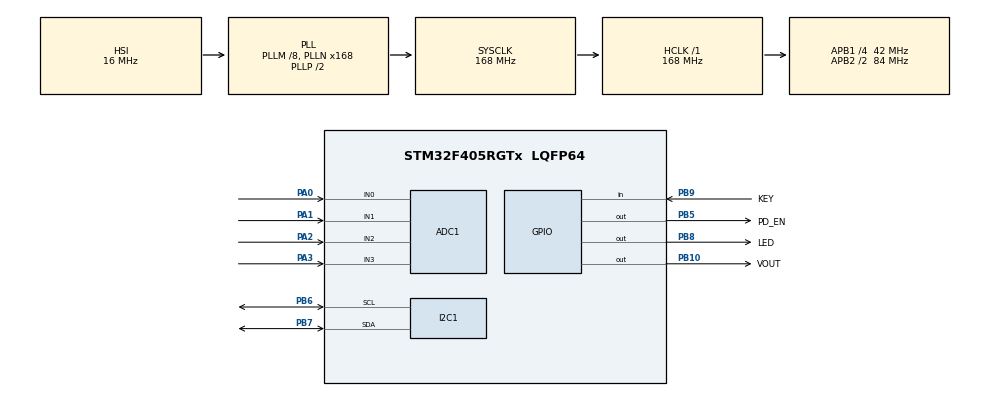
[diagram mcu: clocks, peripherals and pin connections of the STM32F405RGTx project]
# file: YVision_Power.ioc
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ADC1.Channel-0\#ChannelRegularConversion=ADC_CHANNEL_0
ADC1.ContinuousConvMode=ENABLE
ADC1.NbrOfConversionFlag=1
ADC1.Rank-0\#ChannelRegularConversion=1
ADC1.SamplingTime-0\#ChannelRegularConversion=ADC_SAMPLETIME_3CYCLES
ADC1.ScanConvMode=ENABLE
ADC1.master=1
Dma.ADC1.0.Direction=DMA_PERIPH_TO_MEMORY
Dma.ADC1.0.FIFOMode=DMA_FIFOMODE_DISABLE
Dma.ADC1.0.Instance=DMA2_Stream0
Dma.ADC1.0.MemDataAlignment=DMA_MDATAALIGN_HALFWORD
Dma.ADC1.0.MemInc=DMA_MINC_ENABLE
Dma.ADC1.0.Mode=DMA_CIRCULAR
Dma.ADC1.0.PeriphDataAlignment=DMA_PDATAALIGN_HALFWORD
Dma.ADC1.0.PeriphInc=DMA_PINC_DISABLE
Dma.ADC1.0.Priority=DMA_PRIORITY_LOW
Dma.Request0=ADC1
Mcu.Family=STM32F4
Mcu.Name=STM32F405RGTx
Mcu.Package=LQFP64
NVIC.ADC_IRQn=true\:0\:0\:false\:false\:true\:true\:true\:true
NVIC.DMA2_Stream0_IRQn=true\:0\:0\:false\:false\:true\:false\:true\:true
NVIC.PriorityGroup=NVIC_PRIORITYGROUP_4
PA0-WKUP.Signal=ADCx_IN0
PA1.Signal=ADCx_IN1
PA13.Mode=Serial_Wire
PA13.Signal=SYS_JTMS-SWDIO
PA14.Mode=Serial_Wire
PA14.Signal=SYS_JTCK-SWCLK
PA2.Signal=ADCx_IN2
PA3.Signal=ADCx_IN3
PB10.GPIO_Label=VOUT
PB10.Signal=GPIO_Output
PB5.GPIO_Label=PD_EN
PB5.Signal=GPIO_Output
PB6.Mode=I2C
PB6.Signal=I2C1_SCL
PB7.Mode=I2C
PB7.Signal=I2C1_SDA
PB8.GPIO_Label=LED
PB8.Signal=GPIO_Output
PB9.GPIO_Label=KEY
PB9.Signal=GPIO_Input
ProjectManager.HeapSize=0x200
ProjectManager.StackSize=0x400
ProjectManager.TargetToolchain=CMake
RCC.48MHZClocksFreq_Value=84000000
RCC.AHBFreq_Value=168000000
RCC.APB1CLKDivider=RCC_HCLK_DIV4
RCC.APB1Freq_Value=42000000
RCC.APB1TimFreq_Value=84000000
RCC.APB2CLKDivider=RCC_HCLK_DIV2
RCC.APB2Freq_Value=84000000
RCC.APB2TimFreq_Value=168000000
RCC.CortexFreq_Value=168000000
RCC.HCLKFreq_Value=168000000
RCC.HSE_VALUE=25000000
RCC.HSI_VALUE=16000000
RCC.LSE_VALUE=32768
RCC.PLLM=8
RCC.PLLN=168
RCC.SYSCLKFreq_VALUE=168000000
RCC.SYSCLKSource=RCC_SYSCLKSOURCE_PLLCLK
RCC.VCOOutputFreq_Value=336000000
SH.ADCx_IN0.0=ADC1_IN0,IN0
SH.ADCx_IN1.0=ADC1_IN1,IN1
SH.ADCx_IN2.0=ADC1_IN2,IN2
SH.ADCx_IN3.0=ADC1_IN3,IN3
board=custom

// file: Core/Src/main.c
/* USER CODE BEGIN Header */
/**
  ******************************************************************************
  * @file           : main.c
  * @brief          : Main program body
  ******************************************************************************
  * @attention
  *
  * Copyright (c) 2026 STMicroelectronics.
  * All rights reserved.
  *
  * This software is licensed under terms that can be found in the LICENSE file
  * in the root directory of this software component.
  * If no LICENSE file comes with this software, it is provided AS-IS.
  *
  ******************************************************************************
  */
/* USER CODE END Header */
#include "main.h"
#include "adc.h"
#include "dma.h"
#include "i2c.h"
#include "gpio.h"

/* USER CODE BEGIN Includes */
#include "Communication.h"
#include "Joystick.h"
#include "KEY.h"
/* USER CODE END Includes */

void SystemClock_Config(void);

int main(void)
{

  /* MCU Configuration--------------------------------------------------------*/

  /* Reset of all peripherals, Initializes the Flash interface and the Systick. */
  HAL_Init();

  /* Configure the system clock */
  SystemClock_Config();

  /* Initialize all configured peripherals */
  MX_GPIO_Init();
  MX_DMA_Init();
  MX_ADC1_Init();
  MX_I2C1_Init();
  /* USER CODE BEGIN 2 */
  Key_timeinit();
  BQ28Z610_Init();

  /* USER CODE END 2 */

  /* Infinite loop */
  while (1)
  {

    /* USER CODE BEGIN 3 */
    Key_event();
    BQ28Z610_GetData();
    Joystick_Update();
    HAL_Delay(1);

  }
  /* USER CODE END 3 */
}

void SystemClock_Config(void)
{
  RCC_OscInitTypeDef RCC_OscInitStruct = {0};
  RCC_ClkInitTypeDef RCC_ClkInitStruct = {0};

  /** Configure the main internal regulator output voltage
  */
  __HAL_RCC_PWR_CLK_ENABLE();
  __HAL_PWR_VOLTAGESCALING_CONFIG(PWR_REGULATOR_VOLTAGE_SCALE1);

  /** Initializes the RCC Oscillators according to the specified parameters
  * in the RCC_OscInitTypeDef structure.
  */
  RCC_OscInitStruct.OscillatorType = RCC_OSCILLATORTYPE_HSI;
  RCC_OscInitStruct.HSIState = RCC_HSI_ON;
  RCC_OscInitStruct.HSICalibrationValue = RCC_HSICALIBRATION_DEFAULT;
  RCC_OscInitStruct.PLL.PLLState = RCC_PLL_ON;
  RCC_OscInitStruct.PLL.PLLSource = RCC_PLLSOURCE_HSI;
  RCC_OscInitStruct.PLL.PLLM = 8;
  RCC_OscInitStruct.PLL.PLLN = 168;
  RCC_OscInitStruct.PLL.PLLP = RCC_PLLP_DIV2;
  RCC_OscInitStruct.PLL.PLLQ = 4;
  if (HAL_RCC_OscConfig(&RCC_OscInitStruct) != HAL_OK)
  {
    Error_Handler();
  }

  /** Initializes the CPU, AHB and APB buses clocks
  */
  RCC_ClkInitStruct.ClockType = RCC_CLOCKTYPE_HCLK|RCC_CLOCKTYPE_SYSCLK
                              |RCC_CLOCKTYPE_PCLK1|RCC_CLOCKTYPE_PCLK2;
  RCC_ClkInitStruct.SYSCLKSource = RCC_SYSCLKSOURCE_PLLCLK;
  RCC_ClkInitStruct.AHBCLKDivider = RCC_SYSCLK_DIV1;
  RCC_ClkInitStruct.APB1CLKDivider = RCC_HCLK_DIV4;
  RCC_ClkInitStruct.APB2CLKDivider = RCC_HCLK_DIV2;

  if (HAL_RCC_ClockConfig(&RCC_ClkInitStruct, FLASH_LATENCY_5) != HAL_OK)
  {
    Error_Handler();
  }
}

void Error_Handler(void)
{
  __disable_irq();
  while (1)
  {
  }
}
